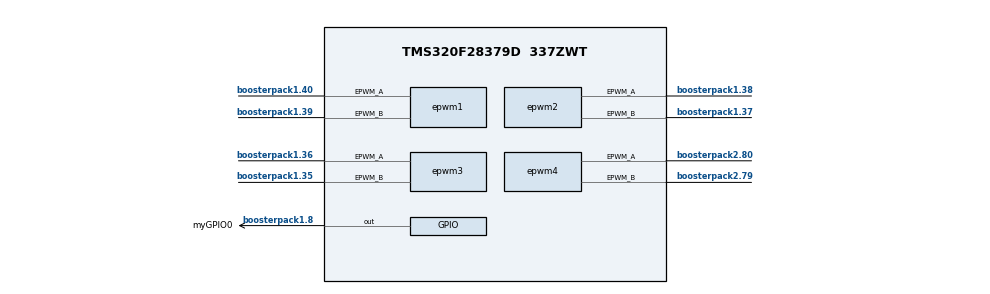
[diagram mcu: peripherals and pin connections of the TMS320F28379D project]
/**
 * These arguments were used when this file was generated. They will be automatically applied on subsequent loads
 * via the GUI or CLI. Run CLI with '--help' for additional information on how to override these arguments.
 * @cliArgs --board "/boards/LAUNCHXL_F28379D" --device "F2837xD" --part "F2837xD_337ZWT" --package "F2837xD_337ZWT" --context "CPU1" --product "C2000WARE@5.04.00.00"
 * @v2CliArgs --board "/boards/LAUNCHXL_F28379D" --device "TMS320F28379D" --package "337ZWT" --context "CPU1" --product "C2000WARE@5.04.00.00"
 * @versions {"tool":"1.22.0+3893"}
 */

/**
 * Import the modules used in this configuration.
 */
const adc   = scripting.addModule("/driverlib/adc.js", {}, false);
const adc1  = adc.addInstance();
const epwm  = scripting.addModule("/driverlib/epwm.js");
const epwm1 = epwm.addInstance();
const epwm2 = epwm.addInstance();
const epwm3 = epwm.addInstance();
const epwm4 = epwm.addInstance();
const gpio  = scripting.addModule("/driverlib/gpio.js", {}, false);
const gpio1 = gpio.addInstance();
const sync  = scripting.addModule("/driverlib/sync.js");

/**
 * Write custom configuration values to the imported modules.
 */
adc1.$name               = "myADC0";
adc1.soc0SampleWindow    = 20;
adc1.interruptPulseMode  = "ADC_PULSE_END_OF_CONV";
adc1.enableInterrupt1    = true;
adc1.soc0Channel         = "ADC_CH_ADCIN1";
adc1.interrupt1SOCSource = "ADC_SOC_NUMBER1";
adc1.adcClockPrescaler   = "ADC_CLK_DIV_4_0";
adc1.enabledSOCs         = ["ADC_SOC_NUMBER0","ADC_SOC_NUMBER1"];
adc1.soc1SampleWindow    = 20;
adc1.soc1Channel         = "ADC_CH_ADCIN2";
adc1.enableInterrupt4    = true;
adc1.enableInterrupt2    = true;
adc1.enabledInts         = ["ADC_INT_NUMBER2"];
adc1.interrupt2SOCSource = "ADC_SOC_NUMBER1";
adc1.soc0Trigger         = "ADC_TRIGGER_EPWM1_SOCA";
adc1.soc1Trigger         = "ADC_TRIGGER_EPWM1_SOCA";

epwm.generateInitFunctions = true;

epwm1.$name                                             = "PhaseA";
epwm1.epwmActionQualifier_t2Source                      = "EPWM_AQ_TRIGGER_EVENT_TRIG_DCA_2";
epwm1.epwmDeadband_enableRED                            = true;
epwm1.epwmDeadband_enableFED                            = true;
epwm1.epwmEventTrigger_enableInterrupt                  = true;
epwm1.epwmEventTrigger_registerInterrupts               = true;
epwm1.epwmEventTrigger_interruptEventCount              = "1";
epwm1.epwmDeadband_polarityFED                          = "EPWM_DB_POLARITY_ACTIVE_LOW";
epwm1.epwmEventTrigger_interruptSource                  = "EPWM_INT_TBCTR_U_CMPC";
epwm1.epwmCounterCompare_cmpC                           = 5;
epwm1.epwmCounterCompare_cmpA                           = 5;
epwm1.epwmCounterCompare_cmpB                           = 5;
epwm1.epwmDeadband_deadbandCounterClockRate             = "EPWM_DB_COUNTER_CLOCK_HALF_CYCLE";
epwm1.epwmDeadband_redShadowMode                        = true;
epwm1.epwmDeadband_fedShadowMode                        = true;
epwm1.epwmDeadband_delayRED                             = 50;
epwm1.epwmDeadband_delayFED                             = 50;
epwm1.epwmEventTrigger_EPWM_SOC_A_triggerEnable         = true;
epwm1.epwmEventTrigger_EPWM_SOC_A_triggerSource         = "EPWM_SOC_TBCTR_U_CMPD";
epwm1.epwmCounterCompare_cmpD                           = 10;
epwm1.epwmEventTrigger_EPWM_SOC_A_triggerEventPrescalar = "10";
epwm1.epwmTimebase_periodLoadMode                       = "EPWM_PERIOD_DIRECT_LOAD";
epwm1.epwmActionQualifier_EPWM_AQ_OUTPUT_A_shadowMode   = true;
epwm1.epwmActionQualifier_EPWM_AQ_OUTPUT_B_shadowMode   = true;
epwm1.hrpwm_syncSource                                  = "HRPWM_PWMSYNC_SOURCE_ZERO";
epwm1.epwmTimebase_periodGld                            = true;
epwm1.epwmCounterCompare_cmpDGld                        = true;
epwm1.$hardware                                         = system.deviceData.board.components.BP_SITE_1.subComponents.PWM_LOC1;
epwm1.epwmTimebase_syncOutPulseMode                     = "EPWM_SYNC_OUT_PULSE_ON_COUNTER_ZERO";
epwm1.epwmCounterCompare_shadowLoadModeCMPA             = "EPWM_COMP_LOAD_ON_CNTR_PERIOD";
epwm1.epwmCounterCompare_shadowLoadModeCMPB             = "EPWM_COMP_LOAD_ON_CNTR_PERIOD";
epwm1.epwmTimebase_hsClockDiv                           = "EPWM_HSCLOCK_DIVIDER_1";
epwm1.epwmTimebase_counterMode                          = "EPWM_COUNTER_MODE_UP";
epwm1.epwmActionQualifier_EPWM_AQ_OUTPUT_A_shadowEvent  = "EPWM_AQ_LOAD_ON_CNTR_PERIOD";
epwm1.epwmActionQualifier_EPWM_AQ_OUTPUT_B_shadowEvent  = "EPWM_AQ_LOAD_ON_CNTR_PERIOD";
epwm1.epwmTimebase_period                               = 7000;
epwm1.epwmInt.enableInterrupt                           = true;
epwm1.epwm.$assign                                      = "EPWM1";
epwm1.epwm.epwm_aPin.$assign                            = "boosterpack1.40";
epwm1.epwm.epwm_bPin.$assign                            = "boosterpack1.39";

epwm2.epwmActionQualifier_t2Source                     = "EPWM_AQ_TRIGGER_EVENT_TRIG_DCA_2";
epwm2.epwmCounterCompare_cmpB                          = 1;
epwm2.epwmDeadband_enableRED                           = true;
epwm2.epwmDeadband_enableFED                           = true;
epwm2.epwmDeadband_polarityFED                         = "EPWM_DB_POLARITY_ACTIVE_LOW";
epwm2.$name                                            = "PhaseB";
epwm2.$hardware                                        = system.deviceData.board.components.BP_SITE_1.subComponents.PWM_LOC2;
epwm2.epwmCounterCompare_cmpA                          = 2;
epwm2.epwmDeadband_deadbandCounterClockRate            = "EPWM_DB_COUNTER_CLOCK_HALF_CYCLE";
epwm2.epwmDeadband_delayRED                            = 50;
epwm2.epwmDeadband_delayFED                            = 50;
epwm2.epwmDeadband_redShadowMode                       = true;
epwm2.epwmDeadband_fedShadowMode                       = true;
epwm2.epwmTimebase_periodLoadMode                      = "EPWM_PERIOD_DIRECT_LOAD";
epwm2.epwmCounterCompare_enableShadowLoadModeCMPD      = false;
epwm2.epwmCounterCompare_enableShadowLoadModeCMPC      = false;
epwm2.epwmActionQualifier_EPWM_AQ_OUTPUT_B_shadowMode  = true;
epwm2.epwmActionQualifier_EPWM_AQ_OUTPUT_A_shadowMode  = true;
epwm2.hrpwm_syncSource                                 = "HRPWM_PWMSYNC_SOURCE_ZERO";
epwm2.epwmTimebase_periodGld                           = true;
epwm2.epwmTimebase_periodLink                          = "EPWM_LINK_WITH_EPWM_1";
epwm2.epwmTimebase_phaseEnable                         = true;
epwm2.epwmCounterCompare_cmpALink                      = "EPWM_LINK_WITH_EPWM_1";
epwm2.epwmCounterCompare_cmpBLink                      = "EPWM_LINK_WITH_EPWM_1";
epwm2.epwmCounterCompare_enableShadowLoadModeCMPB      = false;
epwm2.epwmCounterCompare_enableShadowLoadModeCMPA      = false;
epwm2.epwmTimebase_syncOutPulseMode                    = "EPWM_SYNC_OUT_PULSE_ON_EPWMxSYNCIN";
epwm2.epwmTimebase_hsClockDiv                          = "EPWM_HSCLOCK_DIVIDER_1";
epwm2.epwmTimebase_counterMode                         = "EPWM_COUNTER_MODE_UP";
epwm2.epwmActionQualifier_EPWM_AQ_OUTPUT_B_shadowEvent = "EPWM_AQ_LOAD_ON_CNTR_PERIOD";
epwm2.epwmActionQualifier_EPWM_AQ_OUTPUT_A_shadowEvent = "EPWM_AQ_LOAD_ON_CNTR_PERIOD";
epwm2.epwmTimebase_period                              = 7000;
epwm2.epwm.$assign                                     = "EPWM2";
epwm2.epwm.epwm_aPin.$assign                           = "boosterpack1.38";
epwm2.epwm.epwm_bPin.$assign                           = "boosterpack1.37";

epwm3.epwmActionQualifier_t2Source                     = "EPWM_AQ_TRIGGER_EVENT_TRIG_DCA_2";
epwm3.epwmDeadband_enableRED                           = true;
epwm3.epwmDeadband_enableFED                           = true;
epwm3.epwmDeadband_polarityFED                         = "EPWM_DB_POLARITY_ACTIVE_LOW";
epwm3.$name                                            = "PhaseC";
epwm3.$hardware                                        = system.deviceData.board.components.BP_SITE_1.subComponents.PWM_LOC3;
epwm3.epwmDeadband_deadbandCounterClockRate            = "EPWM_DB_COUNTER_CLOCK_HALF_CYCLE";
epwm3.epwmDeadband_delayRED                            = 50;
epwm3.epwmDeadband_delayFED                            = 50;
epwm3.epwmCounterCompare_cmpA                          = 5;
epwm3.epwmCounterCompare_cmpB                          = 5;
epwm3.epwmTimebase_periodGld                           = true;
epwm3.epwmTimebase_periodLoadMode                      = "EPWM_PERIOD_DIRECT_LOAD";
epwm3.epwmActionQualifier_EPWM_AQ_OUTPUT_B_shadowMode  = true;
epwm3.epwmActionQualifier_EPWM_AQ_OUTPUT_A_shadowMode  = true;
epwm3.epwmCounterCompare_enableShadowLoadModeCMPD      = false;
epwm3.hrpwm_syncSource                                 = "HRPWM_PWMSYNC_SOURCE_ZERO";
epwm3.epwmCounterCompare_shadowLoadModeCMPC            = "EPWM_COMP_LOAD_ON_CNTR_PERIOD";
epwm3.epwmTimebase_periodLink                          = "EPWM_LINK_WITH_EPWM_1";
epwm3.epwmTimebase_phaseEnable                         = true;
epwm3.epwmCounterCompare_cmpALink                      = "EPWM_LINK_WITH_EPWM_1";
epwm3.epwmCounterCompare_cmpBLink                      = "EPWM_LINK_WITH_EPWM_1";
epwm3.epwmCounterCompare_enableShadowLoadModeCMPB      = false;
epwm3.epwmCounterCompare_enableShadowLoadModeCMPA      = false;
epwm3.epwmTimebase_syncOutPulseMode                    = "EPWM_SYNC_OUT_PULSE_ON_EPWMxSYNCIN";
epwm3.epwmTimebase_hsClockDiv                          = "EPWM_HSCLOCK_DIVIDER_1";
epwm3.epwmTimebase_counterMode                         = "EPWM_COUNTER_MODE_UP";
epwm3.epwmActionQualifier_EPWM_AQ_OUTPUT_A_shadowEvent = "EPWM_AQ_LOAD_ON_CNTR_PERIOD";
epwm3.epwmActionQualifier_EPWM_AQ_OUTPUT_B_shadowEvent = "EPWM_AQ_LOAD_ON_CNTR_PERIOD";
epwm3.epwmTimebase_period                              = 7000;
epwm3.epwm.$assign                                     = "EPWM3";
epwm3.epwm.epwm_aPin.$assign                           = "boosterpack1.36";
epwm3.epwm.epwm_bPin.$assign                           = "boosterpack1.35";

epwm4.$hardware                     = system.deviceData.board.components.BP_SITE_2.subComponents.PWM_LOC1;
epwm4.epwmTimebase_period           = 2500;
epwm4.epwmTimebase_counterMode      = "EPWM_COUNTER_MODE_UP";
epwm4.$name                         = "Master";
epwm4.hrpwm_syncSource              = "HRPWM_PWMSYNC_SOURCE_ZERO";
epwm4.epwmTimebase_hsClockDiv       = "EPWM_HSCLOCK_DIVIDER_4";
epwm4.epwmTimebase_forceSyncPulse   = true;
epwm4.epwmTimebase_syncOutPulseMode = "EPWM_SYNC_OUT_PULSE_DISABLED";
epwm4.epwm.$assign                  = "EPWM4";
epwm4.epwm.epwm_aPin.$assign        = "boosterpack2.80";
epwm4.epwm.epwm_bPin.$assign        = "boosterpack2.79";

gpio1.$name             = "myGPIO0";
gpio1.direction         = "GPIO_DIR_MODE_OUT";
gpio1.writeInitialValue = true;
gpio1.gpioPin.$assign   = "boosterpack1.8";
